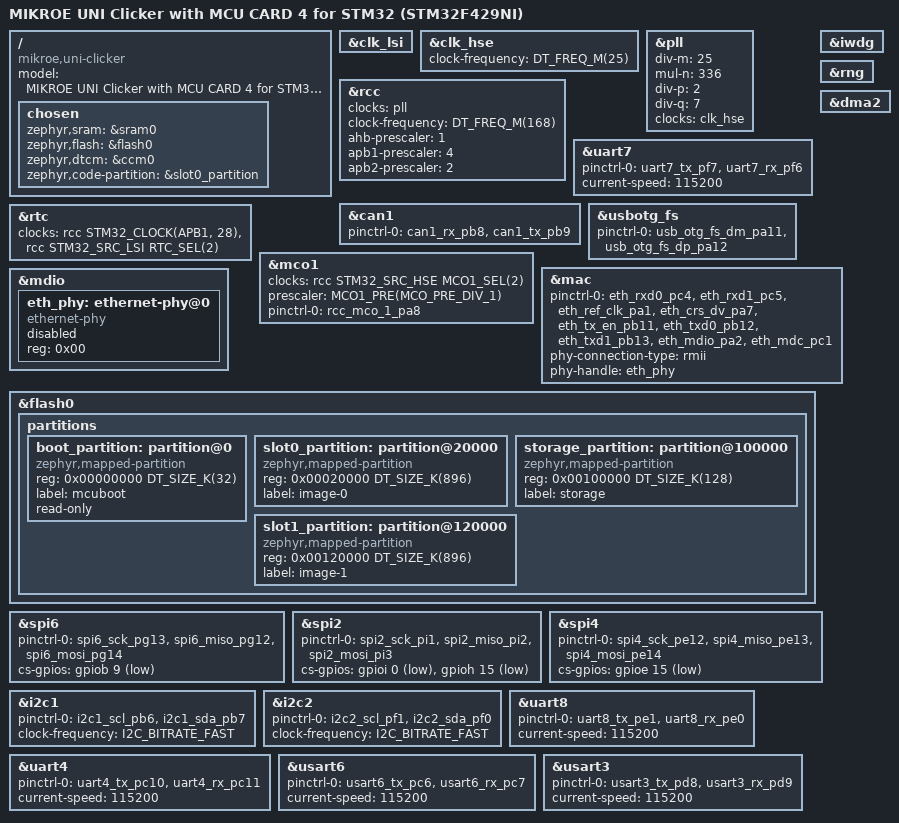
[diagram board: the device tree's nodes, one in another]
/*
 * Copyright (c) 2026 Mario Paja
 *
 * SPDX-License-Identifier: Apache-2.0
 */

/dts-v1/;
#include <st/f4/stm32f429Xi.dtsi>
#include <st/f4/stm32f429nihx-pinctrl.dtsi>
#include <zephyr/dt-bindings/input/input-event-codes.h>
#include "mcu_card_4_stm32f429ni.dtsi"
#include "uni_clicker.dtsi"

/ {
	compatible = "mikroe,uni-clicker";
	model = "MIKROE UNI Clicker with MCU CARD 4 for STM32 (STM32F429NI)";

	chosen {
		zephyr,sram = &sram0;
		zephyr,flash = &flash0;
		zephyr,dtcm = &ccm0;
		zephyr,code-partition = &slot0_partition;
	};
};

&clk_lsi {
	status = "okay";
};

&clk_hse {
	clock-frequency = <DT_FREQ_M(25)>;
	status = "okay";
};

&pll {
	div-m = <25>;
	mul-n = <336>;
	div-p = <2>;
	div-q = <7>;
	clocks = <&clk_hse>;
	status = "okay";
};

&rcc {
	clocks = <&pll>;
	clock-frequency = <DT_FREQ_M(168)>; /* highest value to get a precise USB clock */
	ahb-prescaler = <1>;
	apb1-prescaler = <4>;
	apb2-prescaler = <2>;
};

&uart7 {
	pinctrl-0 = <&uart7_tx_pf7 &uart7_rx_pf6>;
	pinctrl-names = "default";
	current-speed = <115200>;
};

&can1 {
	pinctrl-0 = <&can1_rx_pb8 &can1_tx_pb9>;
	pinctrl-names = "default";
};

zephyr_udc0: &usbotg_fs {
	pinctrl-0 = <&usb_otg_fs_dm_pa11 &usb_otg_fs_dp_pa12>;
	pinctrl-names = "default";
	status = "okay";
};

&rtc {
	clocks = <&rcc STM32_CLOCK(APB1, 28)>,
		 <&rcc STM32_SRC_LSI RTC_SEL(2)>;
	status = "okay";
};

&iwdg {
	status = "okay";
};

&rng {
	status = "okay";
};

&dma2 {
	status = "okay";
};

&mco1 {
	clocks = <&rcc STM32_SRC_HSE MCO1_SEL(2)>;
	prescaler = <MCO1_PRE(MCO_PRE_DIV_1)>;
	pinctrl-0 = <&rcc_mco_1_pa8>;
	pinctrl-names = "default";

	status = "okay";
};

/*
 * The MCU card has an RMII Ethernet PHY, but the UNI Clicker has no RJ45
 * connector or magnetics, so the controller is left disabled.
 */
&mac {
	pinctrl-0 = <&eth_rxd0_pc4
		     &eth_rxd1_pc5
		     &eth_ref_clk_pa1
		     &eth_crs_dv_pa7
		     &eth_tx_en_pb11
		     &eth_txd0_pb12
		     &eth_txd1_pb13
		     &eth_mdio_pa2
		     &eth_mdc_pc1>;
	pinctrl-names = "default";
	phy-connection-type = "rmii";
	phy-handle = <&eth_phy>;
};

&mdio {
	eth_phy: ethernet-phy@0 {
		compatible = "ethernet-phy";
		reg = <0x00>;
		status = "disabled";
	};
};

&flash0 {
	partitions {
		ranges;
		#address-cells = <1>;
		#size-cells = <1>;

		/* 32 KB bootloader */
		boot_partition: partition@0 {
			compatible = "zephyr,mapped-partition";
			reg = <0x00000000 DT_SIZE_K(32)>;
			label = "mcuboot";
			read-only;
		};

		/* Primary image: 896 KB */
		slot0_partition: partition@20000 {
			compatible = "zephyr,mapped-partition";
			reg = <0x00020000 DT_SIZE_K(896)>;
			label = "image-0";
		};

		/* Storage: 128 KB */
		storage_partition: partition@100000 {
			compatible = "zephyr,mapped-partition";
			reg = <0x00100000 DT_SIZE_K(128)>;
			label = "storage";
		};

		/* Secondary image: 896 KB */
		slot1_partition: partition@120000 {
			compatible = "zephyr,mapped-partition";
			reg = <0x00120000 DT_SIZE_K(896)>;
			label = "image-1";
		};
	};
};

/* mikroBUS 1 */
&spi6 {
	pinctrl-0 = <&spi6_sck_pg13 &spi6_miso_pg12 &spi6_mosi_pg14>;
	pinctrl-names = "default";
	cs-gpios = <&gpiob 9 (GPIO_ACTIVE_LOW | GPIO_PULL_UP)>;
};

/* mikroBUS 2 (CS 0) and mikroBUS 3 (CS 1) */
&spi2 {
	pinctrl-0 = <&spi2_sck_pi1 &spi2_miso_pi2 &spi2_mosi_pi3>;
	pinctrl-names = "default";
	cs-gpios = <&gpioi 0 (GPIO_ACTIVE_LOW | GPIO_PULL_UP)>,
		   <&gpioh 15 (GPIO_ACTIVE_LOW | GPIO_PULL_UP)>;
};

/* mikroBUS 4 */
&spi4 {
	pinctrl-0 = <&spi4_sck_pe12 &spi4_miso_pe13 &spi4_mosi_pe14>;
	pinctrl-names = "default";
	cs-gpios = <&gpioe 15 (GPIO_ACTIVE_LOW | GPIO_PULL_UP)>;
};

/* mikroBUS 2 and mikroBUS 3 */
&i2c1 {
	pinctrl-0 = <&i2c1_scl_pb6 &i2c1_sda_pb7>;
	pinctrl-names = "default";
	clock-frequency = <I2C_BITRATE_FAST>;
};

/*
 * mikroBUS 1. mikroBUS 4 is also wired to I2C2 (SCL PH4, SDA PH5): to use it,
 * set pinctrl-0 = <&i2c2_scl_ph4 &i2c2_sda_ph5>.
 */
&i2c2 {
	pinctrl-0 = <&i2c2_scl_pf1 &i2c2_sda_pf0>;
	pinctrl-names = "default";
	clock-frequency = <I2C_BITRATE_FAST>;
};

/* mikroBUS 1 */
&uart8 {
	pinctrl-0 = <&uart8_tx_pe1 &uart8_rx_pe0>;
	pinctrl-names = "default";
	current-speed = <115200>;
};

/* mikroBUS 2 */
&uart4 {
	pinctrl-0 = <&uart4_tx_pc10 &uart4_rx_pc11>;
	pinctrl-names = "default";
	current-speed = <115200>;
};

/* mikroBUS 3 */
&usart6 {
	pinctrl-0 = <&usart6_tx_pc6 &usart6_rx_pc7>;
	pinctrl-names = "default";
	current-speed = <115200>;
};

/* mikroBUS 4 */
&usart3 {
	pinctrl-0 = <&usart3_tx_pd8 &usart3_rx_pd9>;
	pinctrl-names = "default";
	current-speed = <115200>;
};

/*
 * mikroBUS 4 I2C is I2C2 on other pins than mikroBUS 1, so it has no
 * mikrobus_4_i2c label.
 */
mikrobus_1_i2c: &i2c2 {};

mikrobus_1_spi: &spi6 {};

mikrobus_1_uart: &uart8 {};

mikrobus_2_i2c: &i2c1 {};

mikrobus_2_spi: &spi2 {};

mikrobus_2_uart: &uart4 {};

mikrobus_3_i2c: &i2c1 {};

mikrobus_3_spi: &spi2 {};

mikrobus_3_uart: &usart6 {};

mikrobus_4_spi: &spi4 {};

mikrobus_4_uart: &usart3 {};

mikrobus_i2c: &mikrobus_1_i2c {};

mikrobus_spi: &mikrobus_1_spi {};

mikrobus_uart: &mikrobus_1_uart {};

#include <../boards/common/usb/cdc_acm_serial.dtsi>
